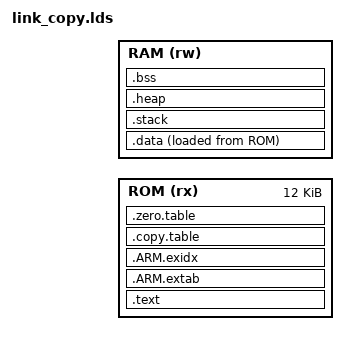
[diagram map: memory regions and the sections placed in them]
__ROM_BASE = ((0x00400000));
__ROM_SIZE = (6 * 1024)*2;
__RAM_BASE = (0x20400000);
__RAM_SIZE = (24*1024)-((2*512));
__STACK_SIZE = 0x00000400;
__HEAP_SIZE = 0x00000000;
MEMORY
{
    ROM (rx) : ORIGIN = __ROM_BASE, LENGTH = __ROM_SIZE
    RAM (rw) : ORIGIN = __RAM_BASE, LENGTH = __RAM_SIZE
}
ENTRY(Reset_Handler)
SECTIONS
{
  .text :
  {
    _stext = ABSOLUTE(.);
    KEEP(*(.vectors))
    *(.text*)
    *(.rodata*)
    * (.*l1_ret_text_*)
    * (.*l1_ret_rodata_*)
    KEEP(*(.init))
    KEEP(*(.fini))
    . = ALIGN(4);
    __fsymtab_start = .;
    KEEP(*(FSymTab))
    __fsymtab_end = .;
    . = ALIGN(4);
    __vsymtab_start = .;
    KEEP(*(VSymTab))
    __vsymtab_end = .;
    . = ALIGN(4);
    __rt_utest_tc_tab_start = .;
    KEEP(*(UtestTcTab))
    __rt_utest_tc_tab_end = .;
    . = ALIGN(4);
    __rt_init_start = .;
    KEEP(*(SORT(.rti_fn*)))
    __rt_init_end = .;
    . = ALIGN(4);
    __SerialTranExport_start__ = .;
    KEEP(*(SerialTranExport))
    __SerialTranExport_end__ = .;
    . = ALIGN(4);
    __sifli_reg_start__ = .;
    KEEP(*(SORT(.sifli_reg*)))
    __sifli_reg_end__ = .;
    KEEP(*(.eh_frame*))
    _etext = ABSOLUTE(.);
  } > ROM
  .ARM.extab :
  {
    *(.ARM.extab* .gnu.linkonce.armextab.*)
  } > ROM
  __exidx_start = .;
  .ARM.exidx :
  {
    *(.ARM.exidx* .gnu.linkonce.armexidx.*)
  } > ROM
  __exidx_end = .;
  .copy.table :
  {
    . = ALIGN(4);
    __copy_table_start__ = .;
    __copy_table_end__ = .;
  } > ROM
  .zero.table :
  {
    . = ALIGN(4);
    __zero_table_start__ = .;
    LONG (__bss_start__)
    LONG (__bss_end__ - __bss_start__)
    __zero_table_end__ = .;
  } > ROM
  __etext = ALIGN (4);
  .data (__etext - __ROM_BASE + __RAM_BASE) :
  {
    _sdata = ABSOLUTE(.);
    __data_start__ = .;
    __RW_IRAM1_start__ = .;
    *(vtable)
    *(.data)
    *(.data.*)
    *(.l1_ret_data_*)
    . = ALIGN(4);
    PROVIDE_HIDDEN (__preinit_array_start = .);
    KEEP(*(.preinit_array))
    PROVIDE_HIDDEN (__preinit_array_end = .);
    . = ALIGN(4);
    _sinit = ABSOLUTE(.);
    PROVIDE(__ctors_start__ = .);
    PROVIDE_HIDDEN (__init_array_start = .);
    KEEP(*(SORT(.ctors.*)))
    KEEP(*(.ctors))
    KEEP(*(SORT(.init_array.*)))
    KEEP(*(.init_array))
    _einit = ABSOLUTE(.);
    PROVIDE_HIDDEN (__init_array_end = .);
    PROVIDE(__ctors_end__ = .);
    . = ALIGN(4);
    PROVIDE(__dtors_start__ = .);
    PROVIDE_HIDDEN (__fini_array_start = .);
    KEEP(*(SORT(.dtors.*)))
    KEEP(*(.dtors))
    KEEP(*(SORT(.fini_array.*)))
    KEEP(*(.fini_array))
    PROVIDE_HIDDEN (__fini_array_end = .);
    PROVIDE(__dtors_end__ = .);
    KEEP(*(.jcr*))
    . = ALIGN(4);
    __data_end__ = .;
    __RW_IRAM1_end__ = .;
    _edata = ABSOLUTE(.);
  } > RAM AT > ROM
  .stack :
  {
    . = ALIGN(8);
    __StackLimit = .;
    . = . + __STACK_SIZE;
    . = ALIGN(8);
    __StackTop = .;
  } > RAM
  PROVIDE(__stack = __StackTop);
  .heap :
  {
    . = ALIGN(8);
    __end__ = .;
    PROVIDE(end = .);
    . = . + __HEAP_SIZE;
    . = ALIGN(8);
    __HeapLimit = .;
  } > RAM
  .bss :
  {
    _sbss = ABSOLUTE(.);
    . = ALIGN(4);
    __bss_start__ = .;
    *(.bss)
    *(.bss.*)
    *(COMMON)
    *(.l1_ret_bss_*)
    . = ALIGN(4);
    __bss_end__ = .;
    __bss_end = .;
    _ebss = ABSOLUTE(.);
    __end__ = .;
    PROVIDE(end = .);
  } > RAM AT > RAM
  ASSERT((LOADADDR(.data) | 0x20000000) == ADDR(.data), "not aligned")
}
